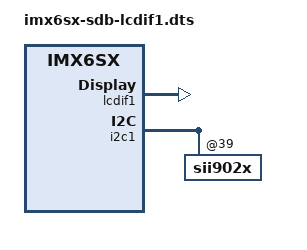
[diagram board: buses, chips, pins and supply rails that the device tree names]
/* SPDX-License-Identifier: GPL-2.0 */
/*
 * Copyright (C) 2014-2015 Freescale Semiconductor, Inc.
 * Copyright 2019 NXP
 */

#include "imx6sx-sdb.dts"

/ {
	sii902x_reset: sii902x-reset {
		status = "okay";
	};
};

&csi1 {
	status = "disabled";
};

&lcdif1 {
	status = "okay";
};

&i2c1 {
	sii902x@39 {
		status = "okay";
	};
};

&ov5640 {
	status = "disabled";
};
